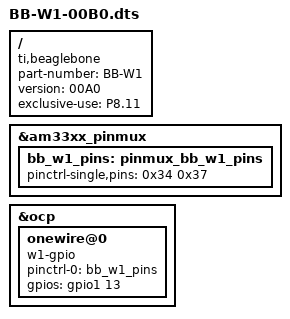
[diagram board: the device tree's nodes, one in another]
/*compile:

    $ dtc -O dtb -o BB-W1-00B0.dtbo -b o -@ BB-W1-00B0.dts

NOTE: on arch linux be sure to install dtc-overlay:

    # pacman -S dtc-overlay


*/

/dts-v1/;
/plugin/;
/ {
        compatible = "ti,beaglebone", "ti,beaglebone-black";
        part-number = "BB-W1";
        version = "00A0";
        
        exclusive-use = "P8.11";
        
        fragment@0 {
                target = <&am33xx_pinmux>;
                __overlay__ {
                        bb_w1_pins: pinmux_bb_w1_pins {
                                pinctrl-single,pins =  <0x34 0x37 /* gpmc_ad13.gpio1_13, OMAP_PIN_INPUT_PULLUP | OMAP_MUX_MODE7 - w1-gpio */ >;
                        };
                };
        };
        
        fragment@1 {
                target = <&ocp>;
                __overlay__ {
                        onewire@0 {
                                status          = "okay";
                                compatible      = "w1-gpio";
                                pinctrl-names   = "default";
                                pinctrl-0       = <&bb_w1_pins>;
                                gpios           = <&gpio1 13 0>;
                        };
                };
        };
};
